# STM32L15xxE register map
File version: 1.0
CPU: 
Registers are 32-bit, read-write, reset 0x0 unless marked. A register's access mark holds for its fields unless they carry their own. Offsets are from the block's base; [hi:lo] are bit positions; {n}, {i} and the like mark numbered series.

## TIM3 — General-purpose timers
Base 0x40000400
Same registers: TIM4 0x40000800, TIM5 0x40000C00
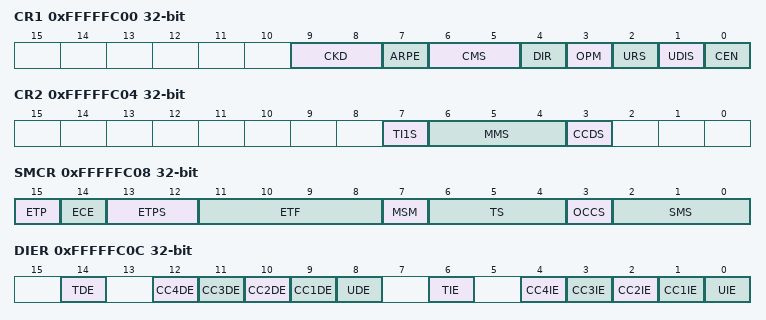
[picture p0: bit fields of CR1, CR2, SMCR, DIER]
0xFFFFFC00 CR1 — control register 1
  [9:8] CKD — Clock division
  [7] ARPE — Auto-reload preload enable
  [6:5] CMS — Center-aligned mode selection
  [4] DIR — Direction
  [3] OPM — One-pulse mode
  [2] URS — Update request source
  [1] UDIS — Update disable
  [0] CEN — Counter enable
0xFFFFFC04 CR2 — control register 2
  [7] TI1S — TI1 selection
  [6:4] MMS — Master mode selection
  [3] CCDS — Capture/compare DMA selection
0xFFFFFC08 SMCR — slave mode control register
  [15] ETP — External trigger polarity
  [14] ECE — External clock enable
  [13:12] ETPS — External trigger prescaler
  [11:8] ETF — External trigger filter
  [7] MSM — Master/Slave mode
  [6:4] TS — Trigger selection
  [3] OCCS — OCREF clear selection
  [2:0] SMS — Slave mode selection
0xFFFFFC0C DIER wo — Interrupt enable register
  [14] TDE — Trigger DMA request enable
  [n+8] CC{n}DE (n=1..4) — Capture/Compare {n} DMA request enable
  [8] UDE — Update DMA request enable
  [6] TIE — Trigger interrupt enable
  [n] CC{n}IE (n=1..4) — Capture/Compare {n} interrupt enable
  [0] UIE — Update interrupt enable
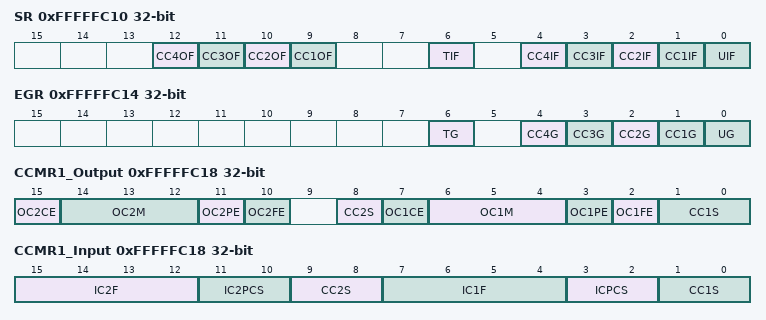
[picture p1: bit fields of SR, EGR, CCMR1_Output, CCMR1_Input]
0xFFFFFC10 SR — status register
  [12] CC4OF — Capture/compare 1 overcapture flag
  [11] CC3OF — Capture/compare 3 overcapture flag
  [10] CC2OF — Capture/compare 2 overcapture flag
  [9] CC1OF — Capture/compare 1 overcapture flag
  [6] TIF — Trigger interrupt flag
  [n] CC{n}IF (n=1..4) — Capture/Compare {n} interrupt flag
  [0] UIF — Update interrupt flag
0xFFFFFC14 EGR — event generation register
  [6] TG — Trigger generation
  [n] CC{n}G (n=1..4) — Capture/compare {n} generation
  [0] UG — Update generation
0xFFFFFC18 CCMR1_Output — capture/compare mode register 1
  [15] OC2CE — Output compare 2 clear enable
  [14:12] OC2M — Output compare 2 mode
  [11] OC2PE — Output compare 2 preload enable
  [10] OC2FE — Output compare 2 fast enable
  [8] CC2S — Capture/Compare 2 selection
  [7] OC1CE — Output compare 1 clear enable
  [6:4] OC1M — Output compare 1 mode
  [3] OC1PE — Output compare 1 preload enable
  [2] OC1FE — Output compare 1 fast enable
  [1:0] CC1S — Capture/Compare 1 selection
0xFFFFFC18 CCMR1_Input — capture/compare mode register 1 (input mode)
  [15:12] IC2F — Input capture 2 filter
  [11:10] IC2PCS — Input capture 2 prescaler
  [9:8] CC2S — Capture/Compare 2 selection
  [7:4] IC1F — Input capture 1 filter
  [3:2] ICPCS — Input capture 1 prescaler
  [1:0] CC1S — Capture/Compare 1 selection
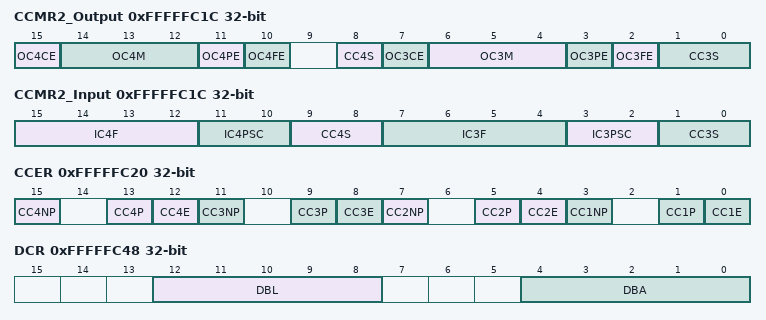
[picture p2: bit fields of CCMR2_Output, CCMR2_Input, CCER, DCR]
0xFFFFFC1C CCMR2_Output — capture/compare mode register 2
  [15] OC4CE — Output compare 4 clear enable
  [14:12] OC4M — Output compare 4 mode
  [11] OC4PE — Output compare 4 preload enable
  [10] OC4FE — Output compare 4 fast enable
  [8] CC4S — Capture/Compare 4 selection
  [7] OC3CE — Output compare 3 clear enable
  [6:4] OC3M — Output compare 3 mode
  [3] OC3PE — Output compare 3 preload enable
  [2] OC3FE — Output compare 3 fast enable
  [1:0] CC3S — Capture/Compare 3 selection
0xFFFFFC1C CCMR2_Input — capture/compare mode register 2 (input mode)
  [15:12] IC4F — Input capture 4 filter
  [11:10] IC4PSC — Input capture 4 prescaler
  [9:8] CC4S — Capture/Compare 4 selection
  [7:4] IC3F — Input capture 3 filter
  [3:2] IC3PSC — Input capture 3 prescaler
  [1:0] CC3S — Capture/compare 3 selection
0xFFFFFC20 CCER — capture/compare enable register
  [15] CC4NP — Capture/Compare 4 output Polarity
  [4n-3] CC{n}P (n=1..4) — Capture/Compare {n} output Polarity
  [4n-4] CC{n}E (n=1..4) — Capture/Compare {n} output enable
  [11] CC3NP — Capture/Compare 3 output Polarity
  [7] CC2NP — Capture/Compare 2 output Polarity
  [3] CC1NP — Capture/Compare 1 complementary output Polarity
0xFFFFFC24 CNT — counter
  [15:0] CNT — TIM2 counter
0xFFFFFC28 PSC — prescaler
  [15:0] PSC — TIM2 prescaler
0xFFFFFC2C ARR — auto-reload register
  [15:0] ARR — Auto-reload value
0xFFFFFC34 CCR1 — capture/compare register 1
  [15:0] CCR1 — Capture/Compare 1 value
0xFFFFFC38 CCR2 — capture/compare register 1
  [15:0] CCR2 — Capture/Compare 2 value
0xFFFFFC3C CCR3 — capture/compare register 1
  [15:0] CCR1 — Capture/Compare 1 value
0xFFFFFC40 CCR4 — capture/compare register 1
  [15:0] CCR4 — Capture/Compare 4 value
0xFFFFFC48 DCR — DMA control register
  [12:8] DBL — DMA burst length
  [4:0] DBA — DMA base address
0xFFFFFC4C DMAR — DMA address for full transfer
  [15:0] DMAB — DMA register for burst accesses

## TIM2 — General-purpose timers
Base 0x40000000
Registers as TIM3; these are added or differ:
0xFFFFFC24 CNT — counter
  [15:0] CNT — TIM2 counter
0xFFFFFC28 PSC — prescaler
  [15:0] PSC — TIM2 prescaler
